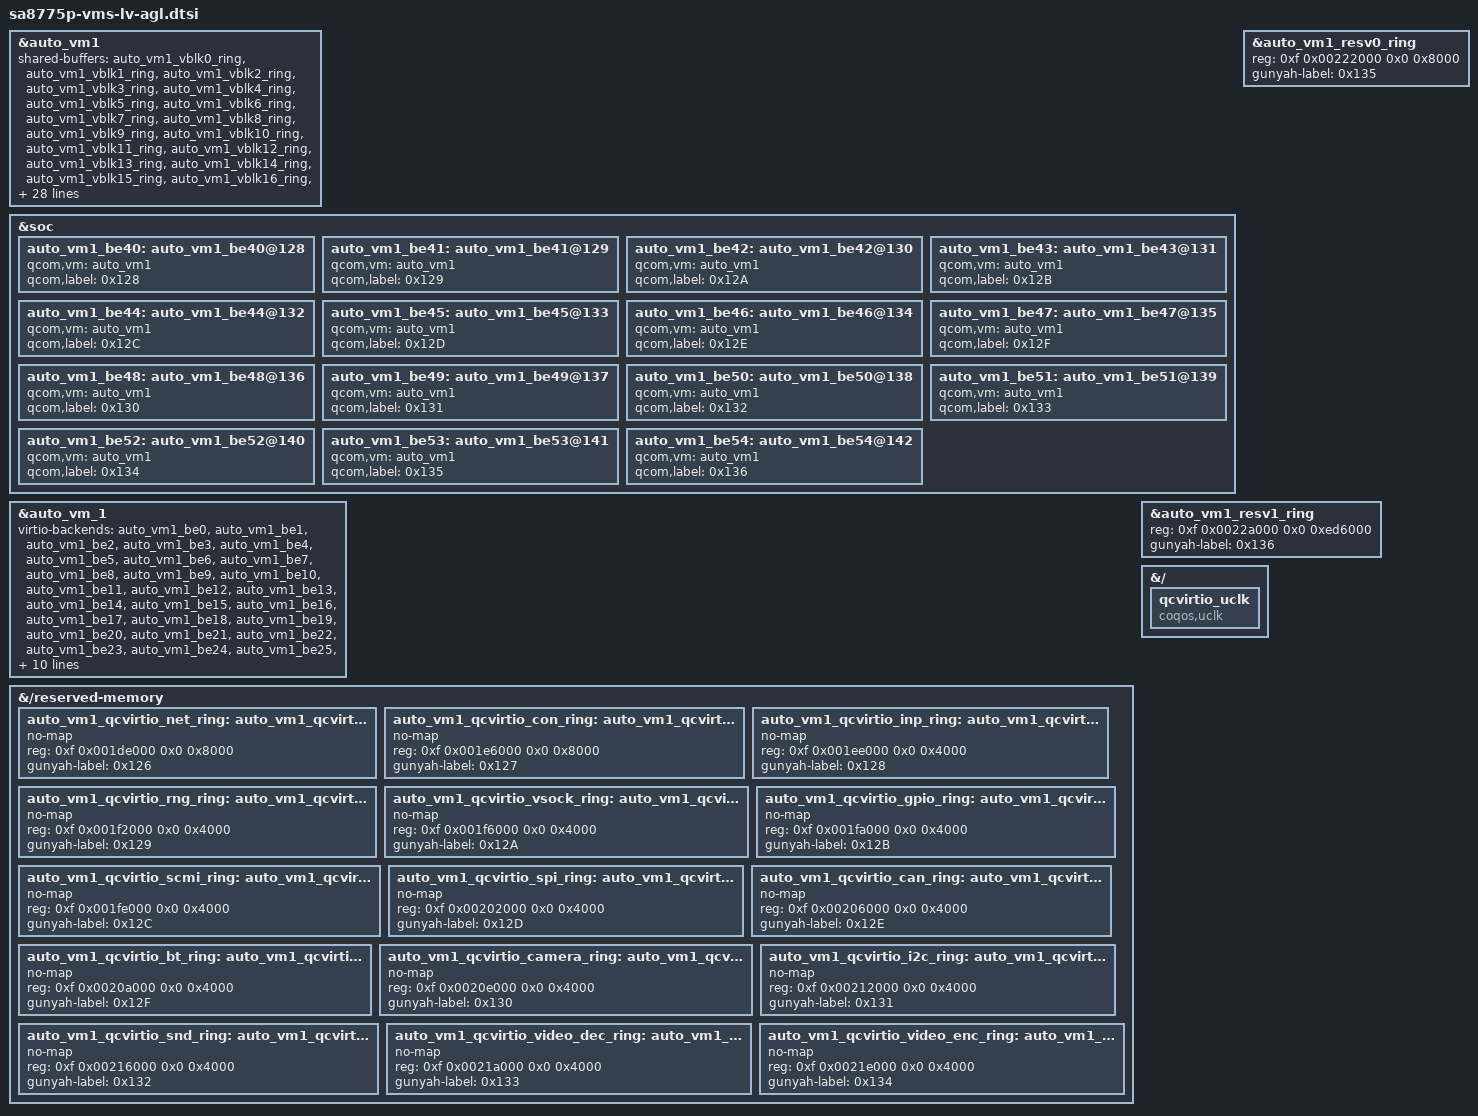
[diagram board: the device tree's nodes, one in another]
// SPDX-License-Identifier: BSD-3-Clause
/*
 * Copyright (c) Qualcomm Technologies, Inc. and/or its subsidiaries.
 */

&auto_vm1 {
	shared-buffers = <&auto_vm1_vblk0_ring
				&auto_vm1_vblk1_ring
				&auto_vm1_vblk2_ring
				&auto_vm1_vblk3_ring
				&auto_vm1_vblk4_ring
				&auto_vm1_vblk5_ring
				&auto_vm1_vblk6_ring
				&auto_vm1_vblk7_ring
				&auto_vm1_vblk8_ring
				&auto_vm1_vblk9_ring
				&auto_vm1_vblk10_ring
				&auto_vm1_vblk11_ring
				&auto_vm1_vblk12_ring
				&auto_vm1_vblk13_ring
				&auto_vm1_vblk14_ring
				&auto_vm1_vblk15_ring
				&auto_vm1_vblk16_ring
				&auto_vm1_vblk17_ring
				&auto_vm1_vblk18_ring
				&auto_vm1_vblk19_ring
				&auto_vm1_vnet0_ring
				&auto_vm1_vnet1_ring
				&auto_vm1_vhab0_ring
				&auto_vm1_vhab1_ring
				&auto_vm1_vhab2_ring
				&auto_vm1_vhab3_ring
				&auto_vm1_vhab4_ring
				&auto_vm1_vhab5_ring
				&auto_vm1_vhab6_ring
				&auto_vm1_vhab7_ring
				&auto_vm1_vhab8_ring
				&auto_vm1_input0_ring
				&auto_vm1_input1_ring
				&auto_vm1_vconsole_ring
				&auto_vm1_i2c0_ring
				&auto_vm1_vscmi_ring
				&auto_vm1_vblk20_ring
				&auto_vm1_vblk21_ring
				&auto_vm1_qcvirtio_net_ring
				&auto_vm1_qcvirtio_con_ring
				&auto_vm1_qcvirtio_inp_ring
				&auto_vm1_qcvirtio_rng_ring
				&auto_vm1_qcvirtio_vsock_ring
				&auto_vm1_qcvirtio_gpio_ring
				&auto_vm1_qcvirtio_scmi_ring
				&auto_vm1_qcvirtio_spi_ring
				&auto_vm1_qcvirtio_can_ring
				&auto_vm1_qcvirtio_bt_ring
				&auto_vm1_qcvirtio_camera_ring
				&auto_vm1_qcvirtio_i2c_ring
				&auto_vm1_qcvirtio_snd_ring
				&auto_vm1_qcvirtio_video_dec_ring
				&auto_vm1_qcvirtio_video_enc_ring
				&auto_vm1_resv0_ring
				&auto_vm1_resv1_ring
				&auto_vm1_swiotlb>;
};

&soc {
	auto_vm1_be40: auto_vm1_be40@128 {
		qcom,vm = <&auto_vm1>;
		qcom,label = <0x128>;
	};

	auto_vm1_be41: auto_vm1_be41@129 {
		qcom,vm = <&auto_vm1>;
		qcom,label = <0x129>;
	};

	auto_vm1_be42: auto_vm1_be42@130 {
		qcom,vm = <&auto_vm1>;
		qcom,label = <0x12A>;
	};

	auto_vm1_be43: auto_vm1_be43@131 {
		qcom,vm = <&auto_vm1>;
		qcom,label = <0x12B>;
	};

	auto_vm1_be44: auto_vm1_be44@132 {
		qcom,vm = <&auto_vm1>;
		qcom,label = <0x12C>;
	};

	auto_vm1_be45: auto_vm1_be45@133 {
		qcom,vm = <&auto_vm1>;
		qcom,label = <0x12D>;
	};

	auto_vm1_be46: auto_vm1_be46@134 {
		qcom,vm = <&auto_vm1>;
		qcom,label = <0x12E>;
	};

	auto_vm1_be47: auto_vm1_be47@135 {
		qcom,vm = <&auto_vm1>;
		qcom,label = <0x12F>;
	};

	auto_vm1_be48: auto_vm1_be48@136 {
		qcom,vm = <&auto_vm1>;
		qcom,label = <0x130>;
	};

	auto_vm1_be49: auto_vm1_be49@137 {
		qcom,vm = <&auto_vm1>;
		qcom,label = <0x131>;
	};

	auto_vm1_be50: auto_vm1_be50@138 {
		qcom,vm = <&auto_vm1>;
		qcom,label = <0x132>;
	};

	auto_vm1_be51: auto_vm1_be51@139 {
		qcom,vm = <&auto_vm1>;
		qcom,label = <0x133>;
	};

	auto_vm1_be52: auto_vm1_be52@140 {
		qcom,vm = <&auto_vm1>;
		qcom,label = <0x134>;
	};

	auto_vm1_be53: auto_vm1_be53@141 {
		qcom,vm = <&auto_vm1>;
		qcom,label = <0x135>;
	};

	auto_vm1_be54: auto_vm1_be54@142 {
		qcom,vm = <&auto_vm1>;
		qcom,label = <0x136>;
	};
};

&auto_vm_1 {
	virtio-backends = <&auto_vm1_be0
				&auto_vm1_be1
				&auto_vm1_be2
				&auto_vm1_be3
				&auto_vm1_be4
				&auto_vm1_be5
				&auto_vm1_be6
				&auto_vm1_be7
				&auto_vm1_be8
				&auto_vm1_be9
				&auto_vm1_be10
				&auto_vm1_be11
				&auto_vm1_be12
				&auto_vm1_be13
				&auto_vm1_be14
				&auto_vm1_be15
				&auto_vm1_be16
				&auto_vm1_be17
				&auto_vm1_be18
				&auto_vm1_be19
				&auto_vm1_be20
				&auto_vm1_be21
				&auto_vm1_be22
				&auto_vm1_be23
				&auto_vm1_be24
				&auto_vm1_be25
				&auto_vm1_be26
				&auto_vm1_be27
				&auto_vm1_be28
				&auto_vm1_be29
				&auto_vm1_be30
				&auto_vm1_be31
				&auto_vm1_be32
				&auto_vm1_be33
				&auto_vm1_be34
				&auto_vm1_be35
				&auto_vm1_be36
				&auto_vm1_be37
				&auto_vm1_be38
				&auto_vm1_be39
				&auto_vm1_be40
				&auto_vm1_be41
				&auto_vm1_be42
				&auto_vm1_be43
				&auto_vm1_be44
				&auto_vm1_be45
				&auto_vm1_be46
				&auto_vm1_be47
				&auto_vm1_be48
				&auto_vm1_be49
				&auto_vm1_be50
				&auto_vm1_be51
				&auto_vm1_be52
				&auto_vm1_be53
				&auto_vm1_be54
		>;
};

&{/reserved-memory} {
	auto_vm1_qcvirtio_net_ring: auto_vm1_qcvirtio_net_ring@f001de000 {
		no-map;
		reg = <0xf 0x001de000 0x0 0x8000>;
		gunyah-label = <0x126>;
	};

	auto_vm1_qcvirtio_con_ring: auto_vm1_qcvirtio_con_ring@f001e6000 {
		no-map;
		reg = <0xf 0x001e6000 0x0 0x8000>;
		gunyah-label = <0x127>;
	};

	auto_vm1_qcvirtio_inp_ring: auto_vm1_qcvirtio_inp_ring@f001ee000 {
		no-map;
		reg = <0xf 0x001ee000 0x0 0x4000>;
		gunyah-label = <0x128>;
	};

	auto_vm1_qcvirtio_rng_ring: auto_vm1_qcvirtio_rng_ring@f001f2000 {
		no-map;
		reg = <0xf 0x001f2000 0x0 0x4000>;
		gunyah-label = <0x129>;
	};

	auto_vm1_qcvirtio_vsock_ring: auto_vm1_qcvirtio_vsock_ring@f001f6000 {
		no-map;
		reg = <0xf 0x001f6000 0x0 0x4000>;
		gunyah-label = <0x12A>;
	};

	auto_vm1_qcvirtio_gpio_ring: auto_vm1_qcvirtio_gpio_ring@f001fa000 {
		no-map;
		reg = <0xf 0x001fa000 0x0 0x4000>;
		gunyah-label = <0x12B>;
	};

	auto_vm1_qcvirtio_scmi_ring: auto_vm1_qcvirtio_scmi_ring@f001fe000 {
		no-map;
		reg = <0xf 0x001fe000 0x0 0x4000>;
		gunyah-label = <0x12C>;
	};

	auto_vm1_qcvirtio_spi_ring: auto_vm1_qcvirtio_spi_ring@f00202000 {
		no-map;
		reg = <0xf 0x00202000 0x0 0x4000>;
		gunyah-label = <0x12D>;
	};

	auto_vm1_qcvirtio_can_ring: auto_vm1_qcvirtio_can_ring@f00206000 {
		no-map;
		reg = <0xf 0x00206000 0x0 0x4000>;
		gunyah-label = <0x12E>;
	};

	auto_vm1_qcvirtio_bt_ring: auto_vm1_qcvirtio_bt_ring@f0020a000 {
		no-map;
		reg = <0xf 0x0020a000 0x0 0x4000>;
		gunyah-label = <0x12F>;
	};

	auto_vm1_qcvirtio_camera_ring: auto_vm1_qcvirtio_camera_ring@f0020e000 {
		no-map;
		reg = <0xf 0x0020e000 0x0 0x4000>;
		gunyah-label = <0x130>;
	};

	auto_vm1_qcvirtio_i2c_ring: auto_vm1_qcvirtio_i2c_ring@f00212000 {
		no-map;
		reg = <0xf 0x00212000 0x0 0x4000>;
		gunyah-label = <0x131>;
	};

	auto_vm1_qcvirtio_snd_ring: auto_vm1_qcvirtio_snd_ring@f00216000 {
		no-map;
		reg = <0xf 0x00216000 0x0 0x4000>;
		gunyah-label = <0x132>;
	};

	auto_vm1_qcvirtio_video_dec_ring: auto_vm1_qcvirtio_video_dec_ring@f0021a000 {
		no-map;
		reg = <0xf 0x0021a000 0x0 0x4000>;
		gunyah-label = <0x133>;
	};

	auto_vm1_qcvirtio_video_enc_ring: auto_vm1_qcvirtio_video_enc_ring@f0021e000 {
		no-map;
		reg = <0xf 0x0021e000 0x0 0x4000>;
		gunyah-label = <0x134>;
	};
};

&auto_vm1_resv0_ring {
	reg = <0xf 0x00222000 0x0 0x8000>;
	gunyah-label = <0x135>;
};

&auto_vm1_resv1_ring {
	reg = <0xf 0x0022a000 0x0 0xed6000>;
	gunyah-label = <0x136>;
};

&{/} {
	// qcvirtio-uclk-driver-linux node
	qcvirtio_uclk {
		compatible = "coqos,uclk";
	};
};
